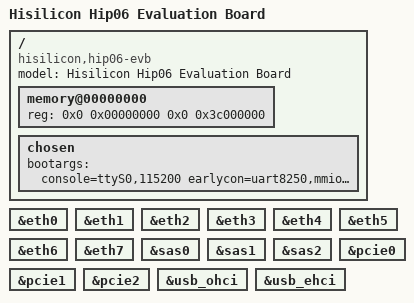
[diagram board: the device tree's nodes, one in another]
/**
 * dts file for Hisilicon EVB
 *
 * Copyright (C) 2016 Hisilicon Ltd.
 *
 * This program is free software; you can redistribute it and/or modify
 * it under the terms of the GNU General Public License version 2 as
 * publishhed by the Free Software Foundation.
 *
 */

/dts-v1/;

/memreserve/ 0x00000000 0x00010000;
/include/ "hip06-evb.dtsi"

/ {
	model = "Hisilicon Hip06 Evaluation Board";
	compatible = "hisilicon,hip06-evb";

	memory@00000000 {
		device_type = "memory";
		reg = <0x0 0x00000000 0x0 0x3c000000>;
	};
	chosen {
		bootargs = "console=ttyS0,115200 earlycon=uart8250,mmio32,0x60300000 initrd=0x7000000,500M";
	};

};

&eth0 {
	status = "ok";
};

&eth1 {
	status = "ok";
};

&eth2 {
	status = "ok";
};

&eth3 {
	status = "ok";
};

&eth4 {
	status = "ok";
};

&eth5 {
	status = "ok";
};

&eth6 {
	status = "ok";
};

&eth7 {
	status = "ok";
};

&sas0 {
	status = "ok";
};

&sas1 {
	status = "ok";
};

&sas2 {
	status = "ok";
};

&pcie0 {
	status = "ok";
};

&pcie1 {
	status = "ok";
};

&pcie2 {
	status = "ok";
};

&usb_ohci {
	status = "ok";
};

&usb_ehci {
	status = "ok";
};
